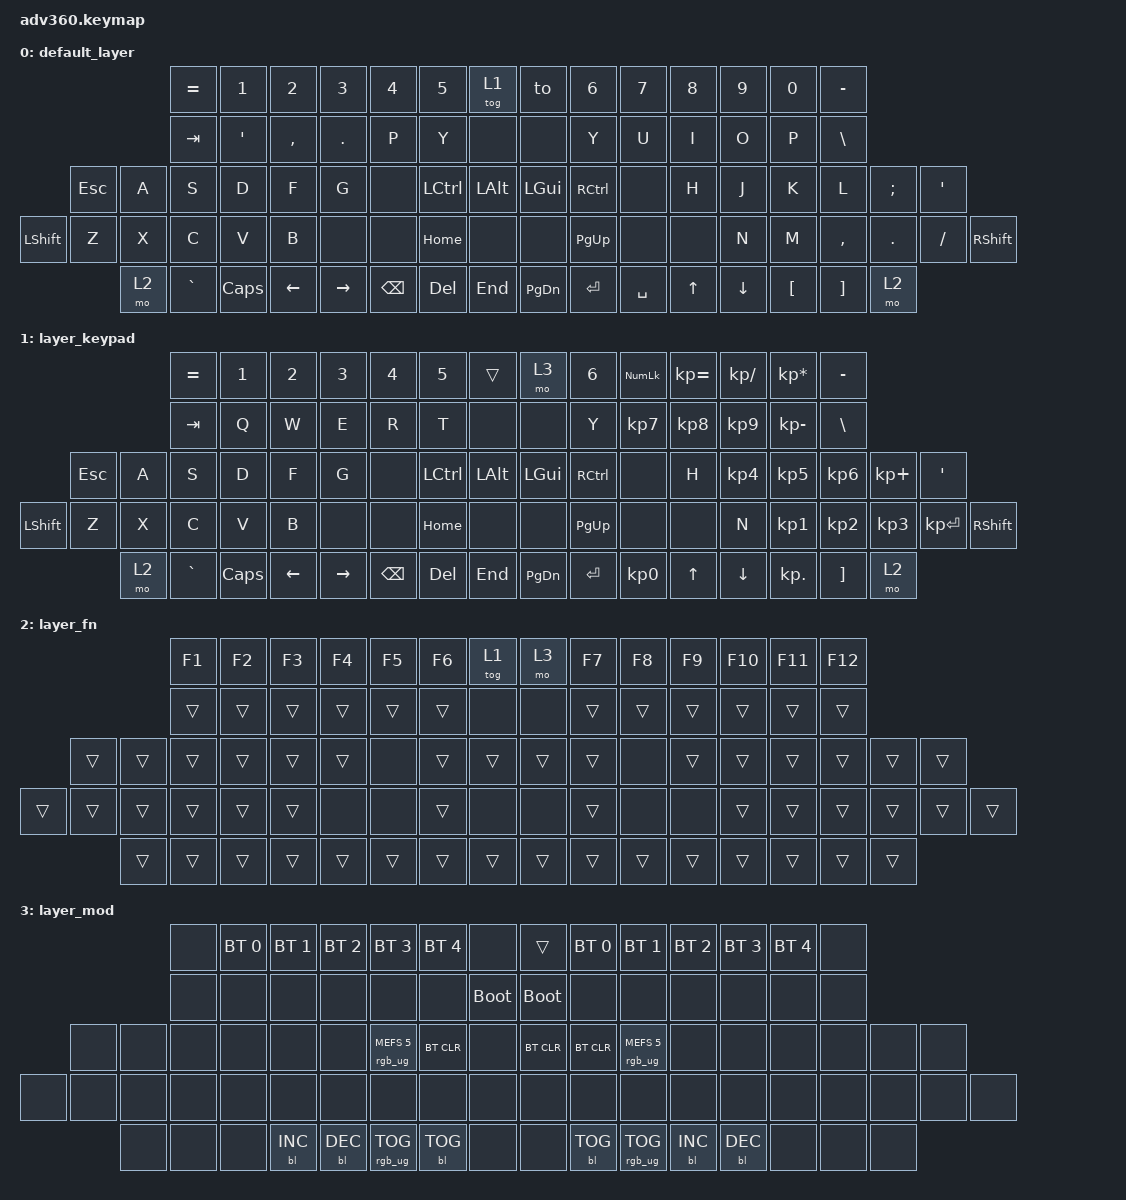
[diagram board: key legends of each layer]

/*
 * Copyright (c) 2020 The ZMK Contributors
 *
 * SPDX-License-Identifier: MIT
 */


/* THIS FILE WAS GENERATED!
 *
 * This file was generated automatically. You may or may not want to
 * edit it directly.
 */

#include <behaviors.dtsi>
#include <dt-bindings/zmk/keys.h>
#include <dt-bindings/zmk/bt.h>
#include <dt-bindings/zmk/rgb.h>
#include <dt-bindings/zmk/backlight.h>

..
#define ___ &trans
#define _x_ &none

/ {
  behaviors {
    #include "macros.dtsi"

    hm: homerow_mods {
        compatible = "zmk,behavior-hold-tap";
        label = "HOMEROW_MODS";
        #binding-cells = <2>;
        tapping-term-ms = <200>;
        quick_tap_ms = <175>;
        flavor = "tap-preferred";
        bindings = <&kp>, <&kp>;
    };
  };

    keymap {
        compatible = "zmk,keymap";


        default_layer {
            bindings = <
 &kp EQUAL     &kp N1     &kp N2      &kp N3     &kp N4    &kp N5             &tog 1        &to     &kp N6     &kp N7     &kp N8     &kp N9     &kp N0  &kp MINUS
   &kp TAB   &kp APOS  &kp COMMA  &kp PERIOD      &kp P     &kp Y              _x_      _x_      &kp Y      &kp U      &kp I      &kp O      &kp P   &kp BSLH
   &kp ESC      &kp A      &kp S       &kp D      &kp F     &kp G              _x_  &kp LCTRL   &kp LALT                         &kp LGUI  &kp RCTRL      _x_     &kp H   &kp J      &kp K    &kp L  &kp SEMI    &kp SQT
 &kp LSHFT      &kp Z      &kp X       &kp C      &kp V     &kp B              _x_      _x_   &kp HOME      _x_      _x_  &kp PG_UP      _x_      _x_     &kp N   &kp M  &kp COMMA  &kp DOT  &kp FSLH  &kp RSHFT
     &mo 2  &kp GRAVE   &kp CAPS    &kp LEFT  &kp RIGHT  &kp BSPC            &kp DEL    &kp END  &kp PG_DN  &kp ENTER  &kp SPACE     &kp UP   &kp DOWN   &kp LBKT  &kp RBKT   &mo 2
            >;
        };

        layer_keypad {
            bindings = <
 &kp EQUAL     &kp N1    &kp N2    &kp N3     &kp N4    &kp N5             &trans      &mo 3     &kp N6  &kp KP_NUM  &kp KP_EQUAL  &kp KP_DIVIDE  &kp KP_MULTIPLY   &kp MINUS
   &kp TAB      &kp Q     &kp W     &kp E      &kp R     &kp T              _x_      _x_      &kp Y   &kp KP_N7     &kp KP_N8      &kp KP_N9     &kp KP_MINUS    &kp BSLH
   &kp ESC      &kp A     &kp S     &kp D      &kp F     &kp G              _x_  &kp LCTRL   &kp LALT                                 &kp LGUI        &kp RCTRL       _x_     &kp H  &kp KP_N4  &kp KP_N5  &kp KP_N6   &kp KP_PLUS    &kp SQT
 &kp LSHFT      &kp Z     &kp X     &kp C      &kp V     &kp B              _x_      _x_   &kp HOME       _x_         _x_      &kp PG_UP            _x_       _x_     &kp N  &kp KP_N1  &kp KP_N2  &kp KP_N3  &kp KP_ENTER  &kp RSHFT
     &mo 2  &kp GRAVE  &kp CAPS  &kp LEFT  &kp RIGHT  &kp BSPC            &kp DEL    &kp END  &kp PG_DN   &kp ENTER     &kp KP_N0         &kp UP         &kp DOWN  &kp KP_DOT  &kp RBKT      &mo 2
            >;
        };

        layer_fn {
            bindings = <
 &kp F1  &kp F2  &kp F3  &kp F4  &kp F5  &kp F6            &tog 1   &mo 3  &kp F7  &kp F8  &kp F9  &kp F10  &kp F11  &kp F12
 &trans  ___  ___  ___  ___  ___             _x_   _x_  ___  ___  ___   ___   ___   ___
 ___  ___  ___  ___  ___  ___             _x_  ___  ___                   ___   ___    _x_  ___  ___  ___  ___  ___  ___
 ___  ___  ___  ___  ___  ___             _x_   _x_  ___   _x_   _x_   ___    _x_    _x_  ___  ___  ___  ___  ___  ___
 ___  ___  ___  ___  ___  ___            ___  ___  ___  ___  ___   ___   ___   ___  ___  ___
            >;
        };

        layer_mod {
            bindings = <
  _x_  &bt BT_SEL 0  &bt BT_SEL 1  &bt BT_SEL 2  &bt BT_SEL 3     &bt BT_SEL 4                             _x_       ___  &bt BT_SEL 0  &bt BT_SEL 1     &bt BT_SEL 2  &bt BT_SEL 3  &bt BT_SEL 4                   _x_
  _x_         _x_         _x_         _x_         _x_            _x_                       &bootloader  &bootloader         _x_         _x_            _x_         _x_         _x_                   _x_
  _x_         _x_         _x_         _x_         _x_            _x_            &rgb_ug RGB_MEFS_CMD 5   &bt BT_CLR         _x_                                   &bt BT_CLR    &bt BT_CLR  &rgb_ug RGB_MEFS_CMD 5   _x_   _x_   _x_   _x_   _x_   _x_
  _x_         _x_         _x_         _x_         _x_            _x_                             _x_        _x_         _x_         _x_            _x_         _x_         _x_                   _x_   _x_   _x_   _x_   _x_   _x_   _x_
  _x_         _x_         _x_    &bl BL_INC    &bl BL_DEC  &rgb_ug RGB_TOG                        &bl BL_TOG        _x_         _x_    &bl BL_TOG  &rgb_ug RGB_TOG    &bl BL_INC    &bl BL_DEC                   _x_   _x_   _x_
            >;
        };

    };
};
